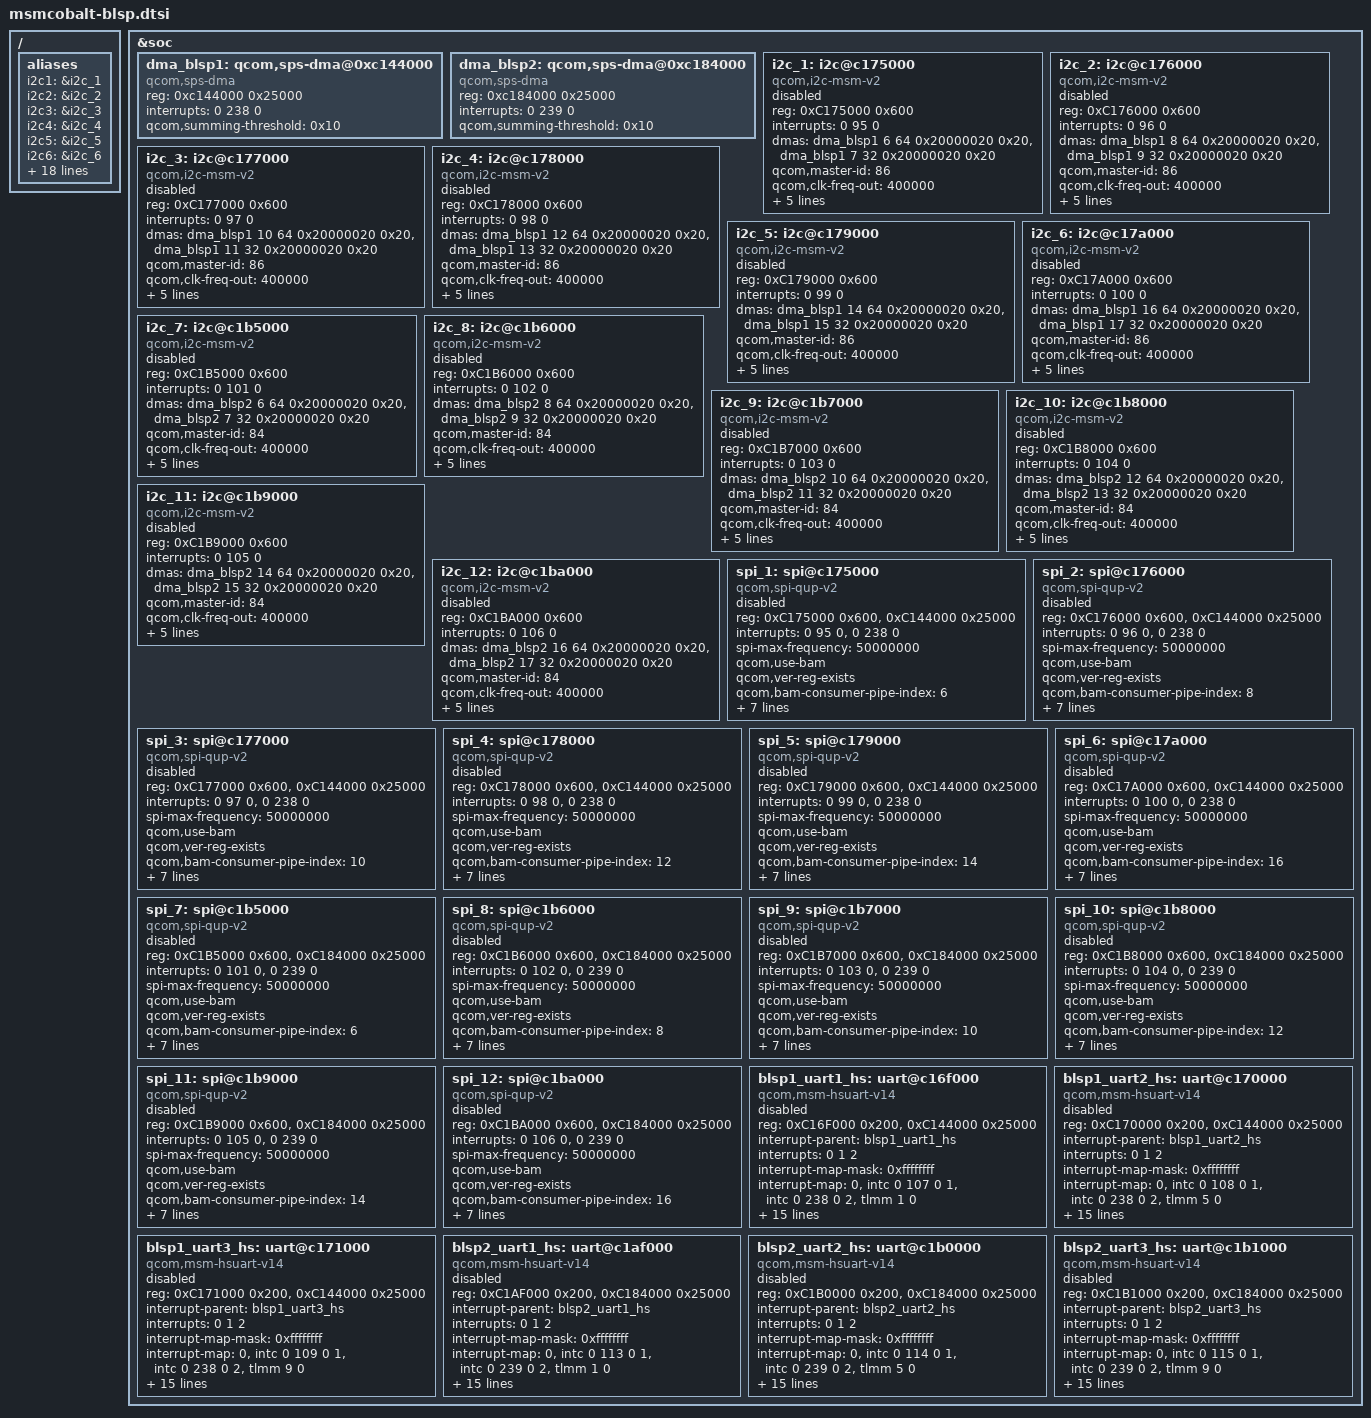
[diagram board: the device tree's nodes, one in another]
/*
 * Copyright (c) 2016, The Linux Foundation. All rights reserved.
 *
 * This program is free software; you can redistribute it and/or modify
 * it under the terms of the GNU General Public License version 2 and
 * only version 2 as published by the Free Software Foundation.
 *
 * This program is distributed in the hope that it will be useful,
 * but WITHOUT ANY WARRANTY; without even the implied warranty of
 * MERCHANTABILITY or FITNESS FOR A PARTICULAR PURPOSE.  See the
 * GNU General Public License for more details.
 */
/ {
	aliases {
		i2c1 = &i2c_1;
		i2c2 = &i2c_2;
		i2c3 = &i2c_3;
		i2c4 = &i2c_4;
		i2c5 = &i2c_5;
		i2c6 = &i2c_6;
		i2c7 = &i2c_7;
		i2c8 = &i2c_8;
		i2c9 = &i2c_9;
		i2c10 = &i2c_10;
		i2c11 = &i2c_11;
		i2c12 = &i2c_12;
		spi1 = &spi_1;
		spi2 = &spi_2;
		spi3 = &spi_3;
		spi4 = &spi_4;
		spi5 = &spi_5;
		spi6 = &spi_6;
		spi7 = &spi_7;
		spi8 = &spi_8;
		spi9 = &spi_9;
		spi10 = &spi_10;
		spi11 = &spi_11;
		spi12 = &spi_12;
	};
};

#include "msmcobalt-pinctrl.dtsi"

&soc {
	dma_blsp1: qcom,sps-dma@0xc144000 { /* BLSP1 */
		#dma-cells = <4>;
		compatible = "qcom,sps-dma";
		reg = <0xc144000 0x25000>;
		interrupts = <0 238 0>;
		qcom,summing-threshold = <0x10>;
	};

	dma_blsp2: qcom,sps-dma@0xc184000 { /* BLSP2 */
		#dma-cells = <4>;
		compatible = "qcom,sps-dma";
		reg = <0xc184000 0x25000>;
		interrupts = <0 239 0>;
		qcom,summing-threshold = <0x10>;
	};

	i2c_1: i2c@c175000 { /* BLSP1 QUP1 */
		compatible = "qcom,i2c-msm-v2";
		#address-cells = <1>;
		#size-cells = <0>;
		reg-names = "qup_phys_addr";
		reg = <0xC175000 0x600>;
		interrupt-names = "qup_irq";
		interrupts = <0 95 0>;
		dmas = <&dma_blsp1 6 64 0x20000020 0x20>,
			<&dma_blsp1 7 32 0x20000020 0x20>;
		dma-names = "tx", "rx";
		qcom,master-id = <86>;
		qcom,clk-freq-out = <400000>;
		qcom,clk-freq-in  = <19200000>;
		clock-names = "iface_clk", "core_clk";
		clocks = <&clock_gcc clk_gcc_blsp1_ahb_clk>,
			 <&clock_gcc clk_gcc_blsp1_qup1_i2c_apps_clk>;
		pinctrl-names = "i2c_active", "i2c_sleep";
		pinctrl-0 = <&i2c_1_active>;
		pinctrl-1 = <&i2c_1_sleep>;
		status = "disabled";
	};

	i2c_2: i2c@c176000 { /* BLSP1 QUP2 */
		compatible = "qcom,i2c-msm-v2";
		#address-cells = <1>;
		#size-cells = <0>;
		reg-names = "qup_phys_addr";
		reg = <0xC176000 0x600>;
		interrupt-names = "qup_irq";
		interrupts = <0 96 0>;
		dmas = <&dma_blsp1 8 64 0x20000020 0x20>,
			<&dma_blsp1 9 32 0x20000020 0x20>;
		dma-names = "tx", "rx";
		qcom,master-id = <86>;
		qcom,clk-freq-out = <400000>;
		qcom,clk-freq-in  = <19200000>;
		clock-names = "iface_clk", "core_clk";
		clocks = <&clock_gcc clk_gcc_blsp1_ahb_clk>,
			 <&clock_gcc clk_gcc_blsp1_qup2_i2c_apps_clk>;
		pinctrl-names = "i2c_active", "i2c_sleep";
		pinctrl-0 = <&i2c_2_active>;
		pinctrl-1 = <&i2c_2_sleep>;
		status = "disabled";
	};

	i2c_3: i2c@c177000 { /* BLSP1 QUP3 */
		compatible = "qcom,i2c-msm-v2";
		#address-cells = <1>;
		#size-cells = <0>;
		reg-names = "qup_phys_addr";
		reg = <0xC177000 0x600>;
		interrupt-names = "qup_irq";
		interrupts = <0 97 0>;
		dmas = <&dma_blsp1 10 64 0x20000020 0x20>,
			<&dma_blsp1 11 32 0x20000020 0x20>;
		dma-names = "tx", "rx";
		qcom,master-id = <86>;
		qcom,clk-freq-out = <400000>;
		qcom,clk-freq-in  = <19200000>;
		clock-names = "iface_clk", "core_clk";
		clocks = <&clock_gcc clk_gcc_blsp1_ahb_clk>,
			 <&clock_gcc clk_gcc_blsp1_qup3_i2c_apps_clk>;
		pinctrl-names = "i2c_active", "i2c_sleep";
		pinctrl-0 = <&i2c_3_active>;
		pinctrl-1 = <&i2c_3_sleep>;
		status = "disabled";
	};

	i2c_4: i2c@c178000 { /* BLSP1 QUP4 */
		compatible = "qcom,i2c-msm-v2";
		#address-cells = <1>;
		#size-cells = <0>;
		reg-names = "qup_phys_addr";
		reg = <0xC178000 0x600>;
		interrupt-names = "qup_irq";
		interrupts = <0 98 0>;
		dmas = <&dma_blsp1 12 64 0x20000020 0x20>,
			<&dma_blsp1 13 32 0x20000020 0x20>;
		dma-names = "tx", "rx";
		qcom,master-id = <86>;
		qcom,clk-freq-out = <400000>;
		qcom,clk-freq-in  = <19200000>;
		clock-names = "iface_clk", "core_clk";
		clocks = <&clock_gcc clk_gcc_blsp1_ahb_clk>,
			 <&clock_gcc clk_gcc_blsp1_qup4_i2c_apps_clk>;
		pinctrl-names = "i2c_active", "i2c_sleep";
		pinctrl-0 = <&i2c_4_active>;
		pinctrl-1 = <&i2c_4_sleep>;
		status = "disabled";
	};

	i2c_5: i2c@c179000 { /* BLSP1 QUP5 */
		compatible = "qcom,i2c-msm-v2";
		#address-cells = <1>;
		#size-cells = <0>;
		reg-names = "qup_phys_addr";
		reg = <0xC179000 0x600>;
		interrupt-names = "qup_irq";
		interrupts = <0 99 0>;
		dmas = <&dma_blsp1 14 64 0x20000020 0x20>,
			<&dma_blsp1 15 32 0x20000020 0x20>;
		dma-names = "tx", "rx";
		qcom,master-id = <86>;
		qcom,clk-freq-out = <400000>;
		qcom,clk-freq-in  = <19200000>;
		clock-names = "iface_clk", "core_clk";
		clocks = <&clock_gcc clk_gcc_blsp1_ahb_clk>,
			 <&clock_gcc clk_gcc_blsp1_qup5_i2c_apps_clk>;
		pinctrl-names = "i2c_active", "i2c_sleep";
		pinctrl-0 = <&i2c_5_active>;
		pinctrl-1 = <&i2c_5_sleep>;
		status = "disabled";
	};

	i2c_6: i2c@c17a000 { /* BLSP1 QUP6 */
		compatible = "qcom,i2c-msm-v2";
		#address-cells = <1>;
		#size-cells = <0>;
		reg-names = "qup_phys_addr";
		reg = <0xC17A000 0x600>;
		interrupt-names = "qup_irq";
		interrupts = <0 100 0>;
		dmas = <&dma_blsp1 16 64 0x20000020 0x20>,
			<&dma_blsp1 17 32 0x20000020 0x20>;
		dma-names = "tx", "rx";
		qcom,master-id = <86>;
		qcom,clk-freq-out = <400000>;
		qcom,clk-freq-in  = <19200000>;
		clock-names = "iface_clk", "core_clk";
		clocks = <&clock_gcc clk_gcc_blsp1_ahb_clk>,
			 <&clock_gcc clk_gcc_blsp1_qup6_i2c_apps_clk>;
		pinctrl-names = "i2c_active", "i2c_sleep";
		pinctrl-0 = <&i2c_6_active>;
		pinctrl-1 = <&i2c_6_sleep>;
		status = "disabled";
	};

	i2c_7: i2c@c1b5000 { /* BLSP2 QUP1 */
		compatible = "qcom,i2c-msm-v2";
		#address-cells = <1>;
		#size-cells = <0>;
		reg-names = "qup_phys_addr";
		reg = <0xC1B5000 0x600>;
		interrupt-names = "qup_irq";
		interrupts = <0 101 0>;
		dmas = <&dma_blsp2 6 64 0x20000020 0x20>,
			<&dma_blsp2 7 32 0x20000020 0x20>;
		dma-names = "tx", "rx";
		qcom,master-id = <84>;
		qcom,clk-freq-out = <400000>;
		qcom,clk-freq-in  = <19200000>;
		clock-names = "iface_clk", "core_clk";
		clocks = <&clock_gcc clk_gcc_blsp2_ahb_clk>,
			 <&clock_gcc clk_gcc_blsp2_qup1_i2c_apps_clk>;
		pinctrl-names = "i2c_active", "i2c_sleep";
		pinctrl-0 = <&i2c_7_active>;
		pinctrl-1 = <&i2c_7_sleep>;
		status = "disabled";
	};

	i2c_8: i2c@c1b6000 { /* BLSP2 QUP2 */
		compatible = "qcom,i2c-msm-v2";
		#address-cells = <1>;
		#size-cells = <0>;
		reg-names = "qup_phys_addr";
		reg = <0xC1B6000 0x600>;
		interrupt-names = "qup_irq";
		interrupts = <0 102 0>;
		dmas = <&dma_blsp2 8 64 0x20000020 0x20>,
			<&dma_blsp2 9 32 0x20000020 0x20>;
		dma-names = "tx", "rx";
		qcom,master-id = <84>;
		qcom,clk-freq-out = <400000>;
		qcom,clk-freq-in  = <19200000>;
		clock-names = "iface_clk", "core_clk";
		clocks = <&clock_gcc clk_gcc_blsp2_ahb_clk>,
			 <&clock_gcc clk_gcc_blsp2_qup2_i2c_apps_clk>;
		pinctrl-names = "i2c_active", "i2c_sleep";
		pinctrl-0 = <&i2c_8_active>;
		pinctrl-1 = <&i2c_8_sleep>;
		status = "disabled";
	};

	i2c_9: i2c@c1b7000 { /* BLSP2 QUP3 */
		compatible = "qcom,i2c-msm-v2";
		#address-cells = <1>;
		#size-cells = <0>;
		reg-names = "qup_phys_addr";
		reg = <0xC1B7000 0x600>;
		interrupt-names = "qup_irq";
		interrupts = <0 103 0>;
		dmas = <&dma_blsp2 10 64 0x20000020 0x20>,
			<&dma_blsp2 11 32 0x20000020 0x20>;
		dma-names = "tx", "rx";
		qcom,master-id = <84>;
		qcom,clk-freq-out = <400000>;
		qcom,clk-freq-in  = <19200000>;
		clock-names = "iface_clk", "core_clk";
		clocks = <&clock_gcc clk_gcc_blsp2_ahb_clk>,
			 <&clock_gcc clk_gcc_blsp2_qup3_i2c_apps_clk>;
		pinctrl-names = "i2c_active", "i2c_sleep";
		pinctrl-0 = <&i2c_9_active>;
		pinctrl-1 = <&i2c_9_sleep>;
		status = "disabled";
	};

	i2c_10: i2c@c1b8000 { /* BLSP2 QUP4 */
		compatible = "qcom,i2c-msm-v2";
		#address-cells = <1>;
		#size-cells = <0>;
		reg-names = "qup_phys_addr";
		reg = <0xC1B8000 0x600>;
		interrupt-names = "qup_irq";
		interrupts = <0 104 0>;
		dmas = <&dma_blsp2 12 64 0x20000020 0x20>,
			<&dma_blsp2 13 32 0x20000020 0x20>;
		dma-names = "tx", "rx";
		qcom,master-id = <84>;
		qcom,clk-freq-out = <400000>;
		qcom,clk-freq-in  = <19200000>;
		clock-names = "iface_clk", "core_clk";
		clocks = <&clock_gcc clk_gcc_blsp2_ahb_clk>,
			 <&clock_gcc clk_gcc_blsp2_qup4_i2c_apps_clk>;
		pinctrl-names = "i2c_active", "i2c_sleep";
		pinctrl-0 = <&i2c_10_active>;
		pinctrl-1 = <&i2c_10_sleep>;
		status = "disabled";
	};

	i2c_11: i2c@c1b9000 { /* BLSP2 QUP5 */
		compatible = "qcom,i2c-msm-v2";
		#address-cells = <1>;
		#size-cells = <0>;
		reg-names = "qup_phys_addr";
		reg = <0xC1B9000 0x600>;
		interrupt-names = "qup_irq";
		interrupts = <0 105 0>;
		dmas = <&dma_blsp2 14 64 0x20000020 0x20>,
			<&dma_blsp2 15 32 0x20000020 0x20>;
		dma-names = "tx", "rx";
		qcom,master-id = <84>;
		qcom,clk-freq-out = <400000>;
		qcom,clk-freq-in  = <19200000>;
		clock-names = "iface_clk", "core_clk";
		clocks = <&clock_gcc clk_gcc_blsp2_ahb_clk>,
			 <&clock_gcc clk_gcc_blsp2_qup5_i2c_apps_clk>;
		pinctrl-names = "i2c_active", "i2c_sleep";
		pinctrl-0 = <&i2c_11_active>;
		pinctrl-1 = <&i2c_11_sleep>;
		status = "disabled";
	};

	i2c_12: i2c@c1ba000 { /* BLSP2 QUP6 */
		compatible = "qcom,i2c-msm-v2";
		#address-cells = <1>;
		#size-cells = <0>;
		reg-names = "qup_phys_addr";
		reg = <0xC1BA000 0x600>;
		interrupt-names = "qup_irq";
		interrupts = <0 106 0>;
		dmas = <&dma_blsp2 16 64 0x20000020 0x20>,
			<&dma_blsp2 17 32 0x20000020 0x20>;
		dma-names = "tx", "rx";
		qcom,master-id = <84>;
		qcom,clk-freq-out = <400000>;
		qcom,clk-freq-in  = <19200000>;
		clock-names = "iface_clk", "core_clk";
		clocks = <&clock_gcc clk_gcc_blsp2_ahb_clk>,
			 <&clock_gcc clk_gcc_blsp2_qup6_i2c_apps_clk>;
		pinctrl-names = "i2c_active", "i2c_sleep";
		pinctrl-0 = <&i2c_12_active>;
		pinctrl-1 = <&i2c_12_sleep>;
		status = "disabled";
	};

	spi_1: spi@c175000 { /* BLSP1 QUP1 */
		compatible = "qcom,spi-qup-v2";
		#address-cells = <1>;
		#size-cells = <0>;
		reg-names = "spi_physical", "spi_bam_physical";
		reg = <0xC175000 0x600>,
		      <0xC144000 0x25000>;
		interrupt-names = "spi_irq", "spi_bam_irq";
		interrupts = <0 95 0>, <0 238 0>;
		spi-max-frequency = <50000000>;
		qcom,use-bam;
		qcom,ver-reg-exists;
		qcom,bam-consumer-pipe-index = <6>;
		qcom,bam-producer-pipe-index = <7>;
		qcom,master-id = <86>;
		qcom,use-pinctrl;
		pinctrl-names = "spi_default", "spi_sleep";
		pinctrl-0 = <&spi_1_active>;
		pinctrl-1 = <&spi_1_sleep>;
		clock-names = "iface_clk", "core_clk";
		clocks = <&clock_gcc clk_gcc_blsp1_ahb_clk>,
			 <&clock_gcc clk_gcc_blsp1_qup1_spi_apps_clk>;
		status = "disabled";
	};

	spi_2: spi@c176000 { /* BLSP1 QUP2 */
		compatible = "qcom,spi-qup-v2";
		#address-cells = <1>;
		#size-cells = <0>;
		reg-names = "spi_physical", "spi_bam_physical";
		reg = <0xC176000 0x600>,
		      <0xC144000 0x25000>;
		interrupt-names = "spi_irq", "spi_bam_irq";
		interrupts = <0 96 0>, <0 238 0>;
		spi-max-frequency = <50000000>;
		qcom,use-bam;
		qcom,ver-reg-exists;
		qcom,bam-consumer-pipe-index = <8>;
		qcom,bam-producer-pipe-index = <9>;
		qcom,master-id = <86>;
		qcom,use-pinctrl;
		pinctrl-names = "spi_default", "spi_sleep";
		pinctrl-0 = <&spi_2_active>;
		pinctrl-1 = <&spi_2_sleep>;
		clock-names = "iface_clk", "core_clk";
		clocks = <&clock_gcc clk_gcc_blsp1_ahb_clk>,
			 <&clock_gcc clk_gcc_blsp1_qup2_spi_apps_clk>;
		status = "disabled";
	};

	spi_3: spi@c177000 { /* BLSP1 QUP3 */
		compatible = "qcom,spi-qup-v2";
		#address-cells = <1>;
		#size-cells = <0>;
		reg-names = "spi_physical", "spi_bam_physical";
		reg = <0xC177000 0x600>,
		      <0xC144000 0x25000>;
		interrupt-names = "spi_irq", "spi_bam_irq";
		interrupts = <0 97 0>, <0 238 0>;
		spi-max-frequency = <50000000>;
		qcom,use-bam;
		qcom,ver-reg-exists;
		qcom,bam-consumer-pipe-index = <10>;
		qcom,bam-producer-pipe-index = <11>;
		qcom,master-id = <86>;
		qcom,use-pinctrl;
		pinctrl-names = "spi_default", "spi_sleep";
		pinctrl-0 = <&spi_3_active>;
		pinctrl-1 = <&spi_3_sleep>;
		clock-names = "iface_clk", "core_clk";
		clocks = <&clock_gcc clk_gcc_blsp1_ahb_clk>,
			 <&clock_gcc clk_gcc_blsp1_qup3_spi_apps_clk>;
		status = "disabled";
	};

	spi_4: spi@c178000 { /* BLSP1 QUP4 */
		compatible = "qcom,spi-qup-v2";
		#address-cells = <1>;
		#size-cells = <0>;
		reg-names = "spi_physical", "spi_bam_physical";
		reg = <0xC178000 0x600>,
		      <0xC144000 0x25000>;
		interrupt-names = "spi_irq", "spi_bam_irq";
		interrupts = <0 98 0>, <0 238 0>;
		spi-max-frequency = <50000000>;
		qcom,use-bam;
		qcom,ver-reg-exists;
		qcom,bam-consumer-pipe-index = <12>;
		qcom,bam-producer-pipe-index = <13>;
		qcom,master-id = <86>;
		qcom,use-pinctrl;
		pinctrl-names = "spi_default", "spi_sleep";
		pinctrl-0 = <&spi_4_active>;
		pinctrl-1 = <&spi_4_sleep>;
		clock-names = "iface_clk", "core_clk";
		clocks = <&clock_gcc clk_gcc_blsp1_ahb_clk>,
			 <&clock_gcc clk_gcc_blsp1_qup4_spi_apps_clk>;
		status = "disabled";
	};

	spi_5: spi@c179000 { /* BLSP1 QUP5 */
		compatible = "qcom,spi-qup-v2";
		#address-cells = <1>;
		#size-cells = <0>;
		reg-names = "spi_physical", "spi_bam_physical";
		reg = <0xC179000 0x600>,
		      <0xC144000 0x25000>;
		interrupt-names = "spi_irq", "spi_bam_irq";
		interrupts = <0 99 0>, <0 238 0>;
		spi-max-frequency = <50000000>;
		qcom,use-bam;
		qcom,ver-reg-exists;
		qcom,bam-consumer-pipe-index = <14>;
		qcom,bam-producer-pipe-index = <15>;
		qcom,master-id = <86>;
		qcom,use-pinctrl;
		pinctrl-names = "spi_default", "spi_sleep";
		pinctrl-0 = <&spi_5_active>;
		pinctrl-1 = <&spi_5_sleep>;
		clock-names = "iface_clk", "core_clk";
		clocks = <&clock_gcc clk_gcc_blsp1_ahb_clk>,
			 <&clock_gcc clk_gcc_blsp1_qup5_spi_apps_clk>;
		status = "disabled";
	};

	spi_6: spi@c17a000 { /* BLSP1 QUP6 */
		compatible = "qcom,spi-qup-v2";
		#address-cells = <1>;
		#size-cells = <0>;
		reg-names = "spi_physical", "spi_bam_physical";
		reg = <0xC17A000 0x600>,
		      <0xC144000 0x25000>;
		interrupt-names = "spi_irq", "spi_bam_irq";
		interrupts = <0 100 0>, <0 238 0>;
		spi-max-frequency = <50000000>;
		qcom,use-bam;
		qcom,ver-reg-exists;
		qcom,bam-consumer-pipe-index = <16>;
		qcom,bam-producer-pipe-index = <17>;
		qcom,master-id = <86>;
		qcom,use-pinctrl;
		pinctrl-names = "spi_default", "spi_sleep";
		pinctrl-0 = <&spi_6_active>;
		pinctrl-1 = <&spi_6_sleep>;
		clock-names = "iface_clk", "core_clk";
		clocks = <&clock_gcc clk_gcc_blsp1_ahb_clk>,
			 <&clock_gcc clk_gcc_blsp1_qup6_spi_apps_clk>;
		status = "disabled";
	};


	spi_7: spi@c1b5000 { /* BLSP2 QUP1 */
		compatible = "qcom,spi-qup-v2";
		#address-cells = <1>;
		#size-cells = <0>;
		reg-names = "spi_physical", "spi_bam_physical";
		reg = <0xC1B5000 0x600>,
		      <0xC184000 0x25000>;
		interrupt-names = "spi_irq", "spi_bam_irq";
		interrupts = <0 101 0>, <0 239 0>;
		spi-max-frequency = <50000000>;
		qcom,use-bam;
		qcom,ver-reg-exists;
		qcom,bam-consumer-pipe-index = <6>;
		qcom,bam-producer-pipe-index = <7>;
		qcom,master-id = <84>;
		qcom,use-pinctrl;
		pinctrl-names = "spi_default", "spi_sleep";
		pinctrl-0 = <&spi_7_active>;
		pinctrl-1 = <&spi_7_sleep>;
		clock-names = "iface_clk", "core_clk";
		clocks = <&clock_gcc clk_gcc_blsp2_ahb_clk>,
			 <&clock_gcc clk_gcc_blsp2_qup1_spi_apps_clk>;
		status = "disabled";
	};

	spi_8: spi@c1b6000 { /* BLSP2 QUP2 */
		compatible = "qcom,spi-qup-v2";
		#address-cells = <1>;
		#size-cells = <0>;
		reg-names = "spi_physical", "spi_bam_physical";
		reg = <0xC1B6000 0x600>,
		      <0xC184000 0x25000>;
		interrupt-names = "spi_irq", "spi_bam_irq";
		interrupts = <0 102 0>, <0 239 0>;
		spi-max-frequency = <50000000>;
		qcom,use-bam;
		qcom,ver-reg-exists;
		qcom,bam-consumer-pipe-index = <8>;
		qcom,bam-producer-pipe-index = <9>;
		qcom,master-id = <84>;
		qcom,use-pinctrl;
		pinctrl-names = "spi_default", "spi_sleep";
		pinctrl-0 = <&spi_8_active>;
		pinctrl-1 = <&spi_8_sleep>;
		clock-names = "iface_clk", "core_clk";
		clocks = <&clock_gcc clk_gcc_blsp2_ahb_clk>,
			 <&clock_gcc clk_gcc_blsp2_qup2_spi_apps_clk>;
		status = "disabled";
	};

	spi_9: spi@c1b7000 { /* BLSP2 QUP3 */
		compatible = "qcom,spi-qup-v2";
		#address-cells = <1>;
		#size-cells = <0>;
		reg-names = "spi_physical", "spi_bam_physical";
		reg = <0xC1B7000 0x600>,
		      <0xC184000 0x25000>;
		interrupt-names = "spi_irq", "spi_bam_irq";
		interrupts = <0 103 0>, <0 239 0>;
		spi-max-frequency = <50000000>;
		qcom,use-bam;
		qcom,ver-reg-exists;
		qcom,bam-consumer-pipe-index = <10>;
		qcom,bam-producer-pipe-index = <11>;
		qcom,master-id = <84>;
		qcom,use-pinctrl;
		pinctrl-names = "spi_default", "spi_sleep";
		pinctrl-0 = <&spi_9_active>;
		pinctrl-1 = <&spi_9_sleep>;
		clock-names = "iface_clk", "core_clk";
		clocks = <&clock_gcc clk_gcc_blsp2_ahb_clk>,
			 <&clock_gcc clk_gcc_blsp2_qup3_spi_apps_clk>;
		status = "disabled";
	};

	spi_10: spi@c1b8000 { /* BLSP2 QUP4 */
		compatible = "qcom,spi-qup-v2";
		#address-cells = <1>;
		#size-cells = <0>;
		reg-names = "spi_physical", "spi_bam_physical";
		reg = <0xC1B8000 0x600>,
		      <0xC184000 0x25000>;
		interrupt-names = "spi_irq", "spi_bam_irq";
		interrupts = <0 104 0>, <0 239 0>;
		spi-max-frequency = <50000000>;
		qcom,use-bam;
		qcom,ver-reg-exists;
		qcom,bam-consumer-pipe-index = <12>;
		qcom,bam-producer-pipe-index = <13>;
		qcom,master-id = <84>;
		qcom,use-pinctrl;
		pinctrl-names = "spi_default", "spi_sleep";
		pinctrl-0 = <&spi_10_active>;
		pinctrl-1 = <&spi_10_sleep>;
		clock-names = "iface_clk", "core_clk";
		clocks = <&clock_gcc clk_gcc_blsp2_ahb_clk>,
			 <&clock_gcc clk_gcc_blsp2_qup4_spi_apps_clk>;
		status = "disabled";
	};

	spi_11: spi@c1b9000 { /* BLSP2 QUP5 */
		compatible = "qcom,spi-qup-v2";
		#address-cells = <1>;
		#size-cells = <0>;
		reg-names = "spi_physical", "spi_bam_physical";
		reg = <0xC1B9000 0x600>,
		      <0xC184000 0x25000>;
		interrupt-names = "spi_irq", "spi_bam_irq";
		interrupts = <0 105 0>, <0 239 0>;
		spi-max-frequency = <50000000>;
		qcom,use-bam;
		qcom,ver-reg-exists;

		qcom,bam-consumer-pipe-index = <14>;
		qcom,bam-producer-pipe-index = <15>;
		qcom,master-id = <84>;
		qcom,use-pinctrl;
		pinctrl-names = "spi_default", "spi_sleep";
		pinctrl-0 = <&spi_11_active>;
		pinctrl-1 = <&spi_11_sleep>;
		clock-names = "iface_clk", "core_clk";
		clocks = <&clock_gcc clk_gcc_blsp2_ahb_clk>,
			 <&clock_gcc clk_gcc_blsp2_qup5_spi_apps_clk>;
		status = "disabled";
	};

	spi_12: spi@c1ba000 { /* BLSP2 QUP6 */
		compatible = "qcom,spi-qup-v2";
		#address-cells = <1>;
		#size-cells = <0>;
		reg-names = "spi_physical", "spi_bam_physical";
		reg = <0xC1BA000 0x600>,
		      <0xC184000 0x25000>;
		interrupt-names = "spi_irq", "spi_bam_irq";
		interrupts = <0 106 0>, <0 239 0>;
		spi-max-frequency = <50000000>;
		qcom,use-bam;
		qcom,ver-reg-exists;
		qcom,bam-consumer-pipe-index = <16>;
		qcom,bam-producer-pipe-index = <17>;
		qcom,master-id = <84>;
		qcom,use-pinctrl;
		pinctrl-names = "spi_default", "spi_sleep";
		pinctrl-0 = <&spi_12_active>;
		pinctrl-1 = <&spi_12_sleep>;
		clock-names = "iface_clk", "core_clk";
		clocks = <&clock_gcc clk_gcc_blsp2_ahb_clk>,
			 <&clock_gcc clk_gcc_blsp2_qup6_spi_apps_clk>;
		status = "disabled";
	};


	blsp1_uart1_hs: uart@c16f000 { /* BLSP1 UART1 */
		compatible = "qcom,msm-hsuart-v14";
		reg = <0xC16F000 0x200>,
		    <0xC144000 0x25000>;
		reg-names = "core_mem", "bam_mem";
		interrupt-names = "core_irq", "bam_irq", "wakeup_irq";
		#address-cells = <0>;
		interrupt-parent = <&blsp1_uart1_hs>;
		interrupts = <0 1 2>;
		#interrupt-cells = <1>;
		interrupt-map-mask = <0xffffffff>;
		interrupt-map = <0 &intc 0 107 0
			    1 &intc 0 238 0
			    2 &tlmm 1 0>;

		qcom,inject-rx-on-wakeup;
		qcom,rx-char-to-inject = <0xFD>;

		qcom,bam-tx-ep-pipe-index = <0>;
		qcom,bam-rx-ep-pipe-index = <1>;
		qcom,master-id = <86>;
		clock-names = "core_clk", "iface_clk";
		clocks = <&clock_gcc clk_gcc_blsp1_uart1_apps_clk>,
		    <&clock_gcc clk_gcc_blsp1_ahb_clk>;
		pinctrl-names = "sleep", "default";
		pinctrl-0 = <&blsp1_uart1_sleep>;
		pinctrl-1 = <&blsp1_uart1_active>;

		qcom,msm-bus,name = "buart1";
		qcom,msm-bus,num-cases = <2>;
		qcom,msm-bus,num-paths = <1>;
		qcom,msm-bus,vectors-KBps =
			    <86 512 0 0>,
			    <86 512 500 800>;
		status = "disabled";
	};

	blsp1_uart2_hs: uart@c170000 { /* BLSP1 UART2 */
		compatible = "qcom,msm-hsuart-v14";
		reg = <0xC170000 0x200>,
		    <0xC144000 0x25000>;
		reg-names = "core_mem", "bam_mem";
		interrupt-names = "core_irq", "bam_irq", "wakeup_irq";
		#address-cells = <0>;
		interrupt-parent = <&blsp1_uart2_hs>;
		interrupts = <0 1 2>;
		#interrupt-cells = <1>;
		interrupt-map-mask = <0xffffffff>;
		interrupt-map = <0 &intc 0 108 0
			    1 &intc 0 238 0
			    2 &tlmm 5 0>;

		qcom,inject-rx-on-wakeup;
		qcom,rx-char-to-inject = <0xFD>;

		qcom,bam-tx-ep-pipe-index = <2>;
		qcom,bam-rx-ep-pipe-index = <3>;
		qcom,master-id = <86>;
		clock-names = "core_clk", "iface_clk";
		clocks = <&clock_gcc clk_gcc_blsp1_uart2_apps_clk>,
		    <&clock_gcc clk_gcc_blsp1_ahb_clk>;
		pinctrl-names = "sleep", "default";
		pinctrl-0 = <&blsp1_uart2_sleep>;
		pinctrl-1 = <&blsp1_uart2_active>;

		qcom,msm-bus,name = "buart2";
		qcom,msm-bus,num-cases = <2>;
		qcom,msm-bus,num-paths = <1>;
		qcom,msm-bus,vectors-KBps =
			    <86 512 0 0>,
			    <86 512 500 800>;
		status = "disabled";
	};

	blsp1_uart3_hs: uart@c171000 { /* BLSP1 UART3 */
		compatible = "qcom,msm-hsuart-v14";
		reg = <0xC171000 0x200>,
		    <0xC144000 0x25000>;
		reg-names = "core_mem", "bam_mem";
		interrupt-names = "core_irq", "bam_irq", "wakeup_irq";
		#address-cells = <0>;
		interrupt-parent = <&blsp1_uart3_hs>;
		interrupts = <0 1 2>;
		#interrupt-cells = <1>;
		interrupt-map-mask = <0xffffffff>;
		interrupt-map = <0 &intc 0 109 0
			    1 &intc 0 238 0
			    2 &tlmm 9 0>;

		qcom,inject-rx-on-wakeup;
		qcom,rx-char-to-inject = <0xFD>;

		qcom,bam-tx-ep-pipe-index = <4>;
		qcom,bam-rx-ep-pipe-index = <5>;
		qcom,master-id = <86>;
		clock-names = "core_clk", "iface_clk";
		clocks = <&clock_gcc clk_gcc_blsp1_uart3_apps_clk>,
		    <&clock_gcc clk_gcc_blsp1_ahb_clk>;
		pinctrl-names = "sleep", "default";
		pinctrl-0 = <&blsp1_uart3_sleep>;
		pinctrl-1 = <&blsp1_uart3_active>;

		qcom,msm-bus,name = "buart3";
		qcom,msm-bus,num-cases = <2>;
		qcom,msm-bus,num-paths = <1>;
		qcom,msm-bus,vectors-KBps =
			    <86 512 0 0>,
			    <86 512 500 800>;
		status = "disabled";
	};

	blsp2_uart1_hs: uart@c1af000 { /* BLSP2 UART1 */
		compatible = "qcom,msm-hsuart-v14";
		reg = <0xC1AF000 0x200>,
		    <0xC184000 0x25000>;
		reg-names = "core_mem", "bam_mem";
		interrupt-names = "core_irq", "bam_irq", "wakeup_irq";
		#address-cells = <0>;
		interrupt-parent = <&blsp2_uart1_hs>;
		interrupts = <0 1 2>;
		#interrupt-cells = <1>;
		interrupt-map-mask = <0xffffffff>;
		interrupt-map = <0 &intc 0 113 0
			    1 &intc 0 239 0
			    2 &tlmm 1 0>;

		qcom,inject-rx-on-wakeup;
		qcom,rx-char-to-inject = <0xFD>;

		qcom,bam-tx-ep-pipe-index = <0>;
		qcom,bam-rx-ep-pipe-index = <1>;
		qcom,master-id = <84>;
		clock-names = "core_clk", "iface_clk";
		clocks = <&clock_gcc clk_gcc_blsp2_uart1_apps_clk>,
		    <&clock_gcc clk_gcc_blsp2_ahb_clk>;
		pinctrl-names = "sleep", "default";
		pinctrl-0 = <&blsp2_uart1_sleep>;
		pinctrl-1 = <&blsp2_uart1_active>;

		qcom,msm-bus,name = "buart1";
		qcom,msm-bus,num-cases = <2>;
		qcom,msm-bus,num-paths = <1>;
		qcom,msm-bus,vectors-KBps =
			    <86 512 0 0>,
			    <86 512 500 800>;
		status = "disabled";
	};

	blsp2_uart2_hs: uart@c1b0000 { /* BLSP2 UART2 */
		compatible = "qcom,msm-hsuart-v14";
		reg = <0xC1B0000 0x200>,
		    <0xC184000 0x25000>;
		reg-names = "core_mem", "bam_mem";
		interrupt-names = "core_irq", "bam_irq", "wakeup_irq";
		#address-cells = <0>;
		interrupt-parent = <&blsp2_uart2_hs>;
		interrupts = <0 1 2>;
		#interrupt-cells = <1>;
		interrupt-map-mask = <0xffffffff>;
		interrupt-map = <0 &intc 0 114 0
			    1 &intc 0 239 0
			    2 &tlmm 5 0>;

		qcom,inject-rx-on-wakeup;
		qcom,rx-char-to-inject = <0xFD>;

		qcom,bam-tx-ep-pipe-index = <2>;
		qcom,bam-rx-ep-pipe-index = <3>;
		qcom,master-id = <84>;
		clock-names = "core_clk", "iface_clk";
		clocks = <&clock_gcc clk_gcc_blsp2_uart2_apps_clk>,
		    <&clock_gcc clk_gcc_blsp2_ahb_clk>;
		pinctrl-names = "sleep", "default";
		pinctrl-0 = <&blsp2_uart2_sleep>;
		pinctrl-1 = <&blsp2_uart2_active>;

		qcom,msm-bus,name = "buart2";
		qcom,msm-bus,num-cases = <2>;
		qcom,msm-bus,num-paths = <1>;
		qcom,msm-bus,vectors-KBps =
			    <86 512 0 0>,
			    <86 512 500 800>;
		status = "disabled";
	};

	blsp2_uart3_hs: uart@c1b1000 { /* BLSP2 UART3 */
		compatible = "qcom,msm-hsuart-v14";
		reg = <0xC1B1000 0x200>,
		    <0xC184000 0x25000>;
		reg-names = "core_mem", "bam_mem";
		interrupt-names = "core_irq", "bam_irq", "wakeup_irq";
		#address-cells = <0>;
		interrupt-parent = <&blsp2_uart3_hs>;
		interrupts = <0 1 2>;
		#interrupt-cells = <1>;
		interrupt-map-mask = <0xffffffff>;
		interrupt-map = <0 &intc 0 115 0
			    1 &intc 0 239 0
			    2 &tlmm 9 0>;

		qcom,inject-rx-on-wakeup;
		qcom,rx-char-to-inject = <0xFD>;

		qcom,bam-tx-ep-pipe-index = <4>;
		qcom,bam-rx-ep-pipe-index = <5>;
		qcom,master-id = <84>;
		clock-names = "core_clk", "iface_clk";
		clocks = <&clock_gcc clk_gcc_blsp2_uart3_apps_clk>,
		    <&clock_gcc clk_gcc_blsp2_ahb_clk>;
		pinctrl-names = "sleep", "default";
		pinctrl-0 = <&blsp2_uart3_sleep>;
		pinctrl-1 = <&blsp2_uart3_active>;

		qcom,msm-bus,name = "buart3";
		qcom,msm-bus,num-cases = <2>;
		qcom,msm-bus,num-paths = <1>;
		qcom,msm-bus,vectors-KBps =
			    <86 512 0 0>,
			    <86 512 500 800>;
		status = "disabled";
	};
};
